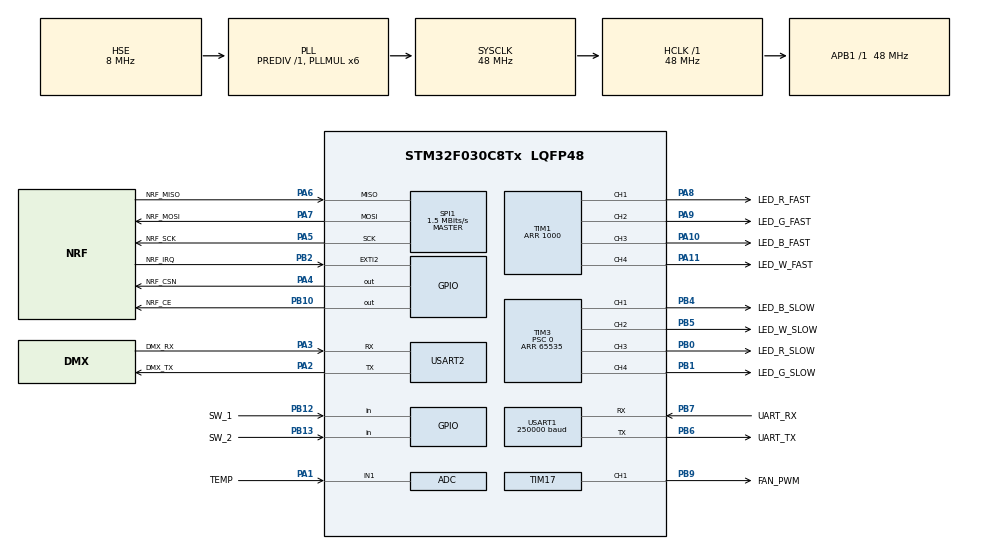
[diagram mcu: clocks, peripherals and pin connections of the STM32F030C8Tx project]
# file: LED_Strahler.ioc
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ADC.ContinuousConvMode=ENABLE
Dma.Request0=USART1_RX
Dma.Request1=USART1_TX
Dma.Request2=SPI1_RX
Dma.Request3=SPI1_TX
Dma.SPI1_RX.2.Direction=DMA_PERIPH_TO_MEMORY
Dma.SPI1_RX.2.Instance=DMA1_Channel2
Dma.SPI1_RX.2.MemDataAlignment=DMA_MDATAALIGN_BYTE
Dma.SPI1_RX.2.MemInc=DMA_MINC_ENABLE
Dma.SPI1_RX.2.Mode=DMA_NORMAL
Dma.SPI1_RX.2.PeriphDataAlignment=DMA_PDATAALIGN_BYTE
Dma.SPI1_RX.2.PeriphInc=DMA_PINC_DISABLE
Dma.SPI1_RX.2.Priority=DMA_PRIORITY_LOW
Dma.SPI1_TX.3.Direction=DMA_MEMORY_TO_PERIPH
Dma.SPI1_TX.3.Instance=DMA1_Channel3
Dma.SPI1_TX.3.MemDataAlignment=DMA_MDATAALIGN_BYTE
Dma.SPI1_TX.3.MemInc=DMA_MINC_ENABLE
Dma.SPI1_TX.3.Mode=DMA_NORMAL
Dma.SPI1_TX.3.PeriphDataAlignment=DMA_PDATAALIGN_BYTE
Dma.SPI1_TX.3.PeriphInc=DMA_PINC_DISABLE
Dma.SPI1_TX.3.Priority=DMA_PRIORITY_LOW
Dma.USART1_RX.0.Direction=DMA_PERIPH_TO_MEMORY
Dma.USART1_RX.0.Instance=DMA1_Channel5
Dma.USART1_RX.0.MemDataAlignment=DMA_MDATAALIGN_BYTE
Dma.USART1_RX.0.MemInc=DMA_MINC_ENABLE
Dma.USART1_RX.0.Mode=DMA_CIRCULAR
Dma.USART1_RX.0.PeriphDataAlignment=DMA_PDATAALIGN_BYTE
Dma.USART1_RX.0.PeriphInc=DMA_PINC_DISABLE
Dma.USART1_RX.0.Priority=DMA_PRIORITY_MEDIUM
Dma.USART1_TX.1.Direction=DMA_MEMORY_TO_PERIPH
Dma.USART1_TX.1.Instance=DMA1_Channel4
Dma.USART1_TX.1.MemDataAlignment=DMA_MDATAALIGN_BYTE
Dma.USART1_TX.1.MemInc=DMA_MINC_ENABLE
Dma.USART1_TX.1.Mode=DMA_CIRCULAR
Dma.USART1_TX.1.PeriphDataAlignment=DMA_PDATAALIGN_BYTE
Dma.USART1_TX.1.PeriphInc=DMA_PINC_DISABLE
Dma.USART1_TX.1.Priority=DMA_PRIORITY_MEDIUM
Mcu.Family=STM32F0
Mcu.Name=STM32F030C8Tx
Mcu.Package=LQFP48
NVIC.DMA1_Channel2_3_IRQn=true\:0\:0\:false\:false\:true\:false\:true
NVIC.DMA1_Channel4_5_IRQn=true\:0\:0\:false\:false\:true\:false\:true
NVIC.EXTI2_3_IRQn=true\:1\:0\:true\:false\:true\:true\:true
PA1.GPIO_Label=TEMP
PA1.Mode=IN1
PA1.Signal=ADC_IN1
PA10.GPIO_Label=LED_B_FAST
PA10.GPIO_ModeDefaultPP=GPIO_MODE_AF_PP
PA10.GPIO_Speed=GPIO_SPEED_FREQ_HIGH
PA10.Signal=S_TIM1_CH3
PA11.GPIO_Label=LED_W_FAST
PA11.GPIO_ModeDefaultPP=GPIO_MODE_AF_PP
PA11.GPIO_Speed=GPIO_SPEED_FREQ_HIGH
PA11.Signal=S_TIM1_CH4
PA13.Mode=Serial_Wire
PA13.Signal=SYS_SWDIO
PA14.Mode=Serial_Wire
PA14.Signal=SYS_SWCLK
PA2.GPIO_Label=DMX_TX
PA2.Mode=Asynchronous
PA2.Signal=USART2_TX
PA3.GPIO_Label=DMX_RX
PA3.GPIO_ModeDefaultPP=GPIO_MODE_AF_OD
PA3.GPIO_PuPd=GPIO_PULLUP
PA3.Mode=Asynchronous
PA3.Signal=USART2_RX
PA4.GPIO_Label=NRF_CSN
PA4.GPIO_Speed=GPIO_SPEED_FREQ_MEDIUM
PA4.PinState=GPIO_PIN_SET
PA4.Signal=GPIO_Output
PA5.GPIO_Label=NRF_SCK
PA5.Mode=Full_Duplex_Master
PA5.Signal=SPI1_SCK
PA6.GPIO_Label=NRF_MISO
PA6.Mode=Full_Duplex_Master
PA6.Signal=SPI1_MISO
PA7.GPIO_Label=NRF_MOSI
PA7.Mode=Full_Duplex_Master
PA7.Signal=SPI1_MOSI
PA8.GPIO_Label=LED_R_FAST
PA8.GPIO_ModeDefaultPP=GPIO_MODE_AF_PP
PA8.GPIO_Speed=GPIO_SPEED_FREQ_HIGH
PA8.Signal=S_TIM1_CH1
PA9.GPIO_Label=LED_G_FAST
PA9.GPIO_ModeDefaultPP=GPIO_MODE_AF_PP
PA9.GPIO_Speed=GPIO_SPEED_FREQ_HIGH
PA9.Signal=S_TIM1_CH2
PB0.GPIO_Label=LED_R_SLOW
PB0.GPIO_ModeDefaultPP=GPIO_MODE_AF_OD
PB0.GPIO_Speed=GPIO_SPEED_FREQ_LOW
PB0.Signal=S_TIM3_CH3
PB1.GPIO_Label=LED_G_SLOW
PB1.GPIO_ModeDefaultPP=GPIO_MODE_AF_OD
PB1.GPIO_Speed=GPIO_SPEED_FREQ_LOW
PB1.Signal=S_TIM3_CH4
PB10.GPIO_Label=NRF_CE
PB10.GPIO_Speed=GPIO_SPEED_FREQ_MEDIUM
PB10.Signal=GPIO_Output
PB12.GPIO_Label=SW_1
PB12.GPIO_PuPd=GPIO_PULLUP
PB12.Signal=GPIO_Input
PB13.GPIO_Label=SW_2
PB13.GPIO_PuPd=GPIO_PULLUP
PB13.Signal=GPIO_Input
PB2.GPIO_Label=NRF_IRQ
PB2.GPIO_ModeDefaultEXTI=GPIO_MODE_IT_FALLING
PB2.GPIO_PuPd=GPIO_PULLUP
PB2.Signal=GPXTI2
PB4.GPIO_Label=LED_B_SLOW
PB4.GPIO_ModeDefaultPP=GPIO_MODE_AF_OD
PB4.Signal=S_TIM3_CH1
PB5.GPIO_Label=LED_W_SLOW
PB5.GPIO_ModeDefaultPP=GPIO_MODE_AF_OD
PB5.Signal=S_TIM3_CH2
PB6.GPIO_Label=UART_TX
PB6.Mode=Asynchronous
PB6.Signal=USART1_TX
PB7.GPIO_Label=UART_RX
PB7.GPIO_ModeDefaultPP=GPIO_MODE_AF_OD
PB7.GPIO_PuPd=GPIO_PULLUP
PB7.Mode=Asynchronous
PB7.Signal=USART1_RX
PB9.GPIO_Label=FAN_PWM
PB9.GPIO_PuPd=GPIO_PULLUP
PB9.GPIO_Speed=GPIO_SPEED_FREQ_MEDIUM
PB9.Signal=S_TIM17_CH1
PF0-OSC_IN.GPIO_Label=OSC_IN
PF0-OSC_IN.Mode=HSE-External-Oscillator
PF0-OSC_IN.Signal=RCC_OSC_IN
PF1-OSC_OUT.GPIO_Label=OSC_OUT
PF1-OSC_OUT.Mode=HSE-External-Oscillator
PF1-OSC_OUT.Signal=RCC_OSC_OUT
ProjectManager.HeapSize=0x200
ProjectManager.StackSize=0x400
ProjectManager.TargetToolchain=STM32CubeIDE
RCC.AHBFreq_Value=48000000
RCC.APB1Freq_Value=48000000
RCC.APB1TimFreq_Value=48000000
RCC.HCLKFreq_Value=48000000
RCC.PLLMUL=RCC_PLL_MUL6
RCC.PLLSourceVirtual=RCC_PLLSOURCE_HSE
RCC.SYSCLKFreq_VALUE=48000000
RCC.SYSCLKSource=RCC_SYSCLKSOURCE_PLLCLK
RCC.TimSys_Div=SYSTICK_CLKSOURCE_HCLK_DIV8
SH.S_TIM17_CH1.0=TIM17_CH1,PWM Generation1 CH1
SH.S_TIM1_CH1.0=TIM1_CH1,PWM Generation1 CH1
SH.S_TIM1_CH2.0=TIM1_CH2,PWM Generation2 CH2
SH.S_TIM1_CH3.0=TIM1_CH3,PWM Generation3 CH3
SH.S_TIM1_CH4.0=TIM1_CH4,PWM Generation4 CH4
SH.S_TIM3_CH1.0=TIM3_CH1,PWM Generation1 CH1
SH.S_TIM3_CH2.0=TIM3_CH2,PWM Generation2 CH2
SH.S_TIM3_CH3.0=TIM3_CH3,PWM Generation3 CH3
SH.S_TIM3_CH4.0=TIM3_CH4,PWM Generation4 CH4
SPI1.BaudRatePrescaler=SPI_BAUDRATEPRESCALER_32
SPI1.CalculateBaudRate=1.5 MBits/s
SPI1.DataSize=SPI_DATASIZE_8BIT
SPI1.Direction=SPI_DIRECTION_2LINES
SPI1.Mode=SPI_MODE_MASTER
SPI1.NSSPMode=SPI_NSS_PULSE_DISABLE
SPI1.VirtualType=VM_MASTER
TIM1.AutoReloadPreload=TIM_AUTORELOAD_PRELOAD_ENABLE
TIM1.Channel-PWM\ Generation1\ CH1=TIM_CHANNEL_1
TIM1.Channel-PWM\ Generation2\ CH2=TIM_CHANNEL_2
TIM1.Channel-PWM\ Generation3\ CH3=TIM_CHANNEL_3
TIM1.Channel-PWM\ Generation4\ CH4=TIM_CHANNEL_4
TIM1.Period=1000
TIM17.AutoReloadPreload=TIM_AUTORELOAD_PRELOAD_ENABLE
TIM17.Channel=TIM_CHANNEL_1
TIM17.OCFastMode_PWM=TIM_OCFAST_ENABLE
TIM17.Period=1920
TIM3.AutoReloadPreload=TIM_AUTORELOAD_PRELOAD_ENABLE
TIM3.Channel-PWM\ Generation1\ CH1=TIM_CHANNEL_1
TIM3.Channel-PWM\ Generation2\ CH2=TIM_CHANNEL_2
TIM3.Channel-PWM\ Generation3\ CH3=TIM_CHANNEL_3
TIM3.Channel-PWM\ Generation4\ CH4=TIM_CHANNEL_4
TIM3.OCPolarity_1=TIM_OCPOLARITY_HIGH
TIM3.OCPolarity_2=TIM_OCPOLARITY_HIGH
TIM3.OCPolarity_3=TIM_OCPOLARITY_HIGH
TIM3.OCPolarity_4=TIM_OCPOLARITY_HIGH
TIM3.Period=65535
TIM3.Prescaler=0
USART1.BaudRate=250000
USART1.VirtualMode-Asynchronous=VM_ASYNC
USART2.VirtualMode-Asynchronous=VM_ASYNC
VP_TIM17_VS_ClockSourceINT.Mode=Enable_Timer
VP_TIM1_VS_ClockSourceINT.Mode=Internal
VP_TIM3_VS_ClockSourceINT.Mode=Internal
board=custom

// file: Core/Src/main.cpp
/* USER CODE BEGIN Header */
/**
  ******************************************************************************
  * @file           : main.c
  * @brief          : Main program body
  ******************************************************************************
  * @attention
  *
  * <h2><center>&copy; Copyright (c) 2019 STMicroelectronics.
  * All rights reserved.</center></h2>
  *
  * This software component is licensed by ST under BSD 3-Clause license,
  * the "License"; You may not use this file except in compliance with the
  * License. You may obtain a copy of the License at:
  *                        opensource.org/licenses/BSD-3-Clause
  *
  ******************************************************************************
  */
/* USER CODE END Header */

#include "main.h"

/* USER CODE BEGIN Includes */
#include "LED_StateMachine.h"
#include "LED_Thermomodel.h"
/* USER CODE END Includes */

ADC_HandleTypeDef hadc;

SPI_HandleTypeDef hspi1;
DMA_HandleTypeDef hdma_spi1_rx;
DMA_HandleTypeDef hdma_spi1_tx;

TIM_HandleTypeDef htim1;
TIM_HandleTypeDef htim3;
TIM_HandleTypeDef htim17;

UART_HandleTypeDef huart1;
UART_HandleTypeDef huart2;
DMA_HandleTypeDef hdma_usart1_rx;
DMA_HandleTypeDef hdma_usart1_tx;

void SystemClock_Config(void);
static void MX_GPIO_Init(void);
static void MX_DMA_Init(void);
static void MX_ADC_Init(void);
static void MX_SPI1_Init(void);
static void MX_TIM1_Init(void);
static void MX_TIM3_Init(void);
static void MX_USART1_UART_Init(void);
static void MX_TIM17_Init(void);
static void MX_USART2_UART_Init(void);

int main(void)
{

  /* MCU Configuration--------------------------------------------------------*/

  /* Reset of all peripherals, Initializes the Flash interface and the Systick. */
  HAL_Init();

  /* Configure the system clock */
  SystemClock_Config();

  /* Initialize all configured peripherals */
  MX_GPIO_Init();
  MX_DMA_Init();
  MX_ADC_Init();
  MX_SPI1_Init();
  MX_TIM1_Init();
  MX_TIM3_Init();
  MX_USART1_UART_Init();
  MX_TIM17_Init();
  MX_USART2_UART_Init();
  /* USER CODE BEGIN 2 */

  LED_Thermomodel_Init();
  LED_StateMachine_Init();

  /* USER CODE END 2 */

  /* Infinite loop */
  /* USER CODE BEGIN WHILE */
	while (1)
	{
		LED_StateMachine_Handle();
		LED_Thermomodel_Handle();
    /* USER CODE END WHILE */

	}
}

void SystemClock_Config(void)
{
  RCC_OscInitTypeDef RCC_OscInitStruct = {0};
  RCC_ClkInitTypeDef RCC_ClkInitStruct = {0};
  RCC_PeriphCLKInitTypeDef PeriphClkInit = {0};

  /** Initializes the CPU, AHB and APB busses clocks
  */
  RCC_OscInitStruct.OscillatorType = RCC_OSCILLATORTYPE_HSI14|RCC_OSCILLATORTYPE_HSE;
  RCC_OscInitStruct.HSEState = RCC_HSE_ON;
  RCC_OscInitStruct.HSI14State = RCC_HSI14_ON;
  RCC_OscInitStruct.HSI14CalibrationValue = 16;
  RCC_OscInitStruct.PLL.PLLState = RCC_PLL_ON;
  RCC_OscInitStruct.PLL.PLLSource = RCC_PLLSOURCE_HSE;
  RCC_OscInitStruct.PLL.PLLMUL = RCC_PLL_MUL6;
  RCC_OscInitStruct.PLL.PREDIV = RCC_PREDIV_DIV1;
  if (HAL_RCC_OscConfig(&RCC_OscInitStruct) != HAL_OK)
  {
    Error_Handler();
  }
  /** Initializes the CPU, AHB and APB busses clocks
  */
  RCC_ClkInitStruct.ClockType = RCC_CLOCKTYPE_HCLK|RCC_CLOCKTYPE_SYSCLK
                              |RCC_CLOCKTYPE_PCLK1;
  RCC_ClkInitStruct.SYSCLKSource = RCC_SYSCLKSOURCE_PLLCLK;
  RCC_ClkInitStruct.AHBCLKDivider = RCC_SYSCLK_DIV1;
  RCC_ClkInitStruct.APB1CLKDivider = RCC_HCLK_DIV1;

  if (HAL_RCC_ClockConfig(&RCC_ClkInitStruct, FLASH_LATENCY_1) != HAL_OK)
  {
    Error_Handler();
  }
  PeriphClkInit.PeriphClockSelection = RCC_PERIPHCLK_USART1;
  PeriphClkInit.Usart1ClockSelection = RCC_USART1CLKSOURCE_PCLK1;
  if (HAL_RCCEx_PeriphCLKConfig(&PeriphClkInit) != HAL_OK)
  {
    Error_Handler();
  }
}

static void MX_ADC_Init(void)
{

  ADC_ChannelConfTypeDef sConfig = {0};

  /** Configure the global features of the ADC (Clock, Resolution, Data Alignment and number of conversion)
  */
  hadc.Instance = ADC1;
  hadc.Init.ClockPrescaler = ADC_CLOCK_ASYNC_DIV1;
  hadc.Init.Resolution = ADC_RESOLUTION_12B;
  hadc.Init.DataAlign = ADC_DATAALIGN_RIGHT;
  hadc.Init.ScanConvMode = ADC_SCAN_DIRECTION_FORWARD;
  hadc.Init.EOCSelection = ADC_EOC_SINGLE_CONV;
  hadc.Init.LowPowerAutoWait = DISABLE;
  hadc.Init.LowPowerAutoPowerOff = DISABLE;
  hadc.Init.ContinuousConvMode = ENABLE;
  hadc.Init.DiscontinuousConvMode = DISABLE;
  hadc.Init.ExternalTrigConv = ADC_SOFTWARE_START;
  hadc.Init.ExternalTrigConvEdge = ADC_EXTERNALTRIGCONVEDGE_NONE;
  hadc.Init.DMAContinuousRequests = DISABLE;
  hadc.Init.Overrun = ADC_OVR_DATA_PRESERVED;
  if (HAL_ADC_Init(&hadc) != HAL_OK)
  {
    Error_Handler();
  }
  /** Configure for the selected ADC regular channel to be converted.
  */
  sConfig.Channel = ADC_CHANNEL_1;
  sConfig.Rank = ADC_RANK_CHANNEL_NUMBER;
  sConfig.SamplingTime = ADC_SAMPLETIME_1CYCLE_5;
  if (HAL_ADC_ConfigChannel(&hadc, &sConfig) != HAL_OK)
  {
    Error_Handler();
  }

}

static void MX_SPI1_Init(void)
{

  /* SPI1 parameter configuration*/
  hspi1.Instance = SPI1;
  hspi1.Init.Mode = SPI_MODE_MASTER;
  hspi1.Init.Direction = SPI_DIRECTION_2LINES;
  hspi1.Init.DataSize = SPI_DATASIZE_8BIT;
  hspi1.Init.CLKPolarity = SPI_POLARITY_LOW;
  hspi1.Init.CLKPhase = SPI_PHASE_1EDGE;
  hspi1.Init.NSS = SPI_NSS_SOFT;
  hspi1.Init.BaudRatePrescaler = SPI_BAUDRATEPRESCALER_32;
  hspi1.Init.FirstBit = SPI_FIRSTBIT_MSB;
  hspi1.Init.TIMode = SPI_TIMODE_DISABLE;
  hspi1.Init.CRCCalculation = SPI_CRCCALCULATION_DISABLE;
  hspi1.Init.CRCPolynomial = 7;
  hspi1.Init.CRCLength = SPI_CRC_LENGTH_DATASIZE;
  hspi1.Init.NSSPMode = SPI_NSS_PULSE_DISABLE;
  if (HAL_SPI_Init(&hspi1) != HAL_OK)
  {
    Error_Handler();
  }
  /* USER CODE BEGIN SPI1_Init 2 */
  /* full duplex master, 8 bit transfer, default phase and polarity */
  hspi1.Instance->CR1 |= SPI_CR1_MSTR | SPI_CR1_SPE | SPI_CR1_SSM | SPI_CR1_SSI;
  /* Disable receive FIFO, it'd complicate things when there is an odd number of bytes to transfer */
  hspi1.Instance->CR2 |= SPI_CR2_FRXTH;
  /* USER CODE END SPI1_Init 2 */

}

static void MX_TIM1_Init(void)
{

  TIM_ClockConfigTypeDef sClockSourceConfig = {0};
  TIM_MasterConfigTypeDef sMasterConfig = {0};
  TIM_OC_InitTypeDef sConfigOC = {0};
  TIM_BreakDeadTimeConfigTypeDef sBreakDeadTimeConfig = {0};

  htim1.Instance = TIM1;
  htim1.Init.Prescaler = 0;
  htim1.Init.CounterMode = TIM_COUNTERMODE_UP;
  htim1.Init.Period = 1000;
  htim1.Init.ClockDivision = TIM_CLOCKDIVISION_DIV1;
  htim1.Init.RepetitionCounter = 0;
  htim1.Init.AutoReloadPreload = TIM_AUTORELOAD_PRELOAD_ENABLE;
  if (HAL_TIM_Base_Init(&htim1) != HAL_OK)
  {
    Error_Handler();
  }
  sClockSourceConfig.ClockSource = TIM_CLOCKSOURCE_INTERNAL;
  if (HAL_TIM_ConfigClockSource(&htim1, &sClockSourceConfig) != HAL_OK)
  {
    Error_Handler();
  }
  if (HAL_TIM_PWM_Init(&htim1) != HAL_OK)
  {
    Error_Handler();
  }
  sMasterConfig.MasterOutputTrigger = TIM_TRGO_RESET;
  sMasterConfig.MasterSlaveMode = TIM_MASTERSLAVEMODE_DISABLE;
  if (HAL_TIMEx_MasterConfigSynchronization(&htim1, &sMasterConfig) != HAL_OK)
  {
    Error_Handler();
  }
  sConfigOC.OCMode = TIM_OCMODE_PWM1;
  sConfigOC.Pulse = 0;
  sConfigOC.OCPolarity = TIM_OCPOLARITY_HIGH;
  sConfigOC.OCNPolarity = TIM_OCNPOLARITY_HIGH;
  sConfigOC.OCFastMode = TIM_OCFAST_DISABLE;
  sConfigOC.OCIdleState = TIM_OCIDLESTATE_RESET;
  sConfigOC.OCNIdleState = TIM_OCNIDLESTATE_RESET;
  if (HAL_TIM_PWM_ConfigChannel(&htim1, &sConfigOC, TIM_CHANNEL_1) != HAL_OK)
  {
    Error_Handler();
  }
  if (HAL_TIM_PWM_ConfigChannel(&htim1, &sConfigOC, TIM_CHANNEL_2) != HAL_OK)
  {
    Error_Handler();
  }
  if (HAL_TIM_PWM_ConfigChannel(&htim1, &sConfigOC, TIM_CHANNEL_3) != HAL_OK)
  {
    Error_Handler();
  }
  if (HAL_TIM_PWM_ConfigChannel(&htim1, &sConfigOC, TIM_CHANNEL_4) != HAL_OK)
  {
    Error_Handler();
  }
  sBreakDeadTimeConfig.OffStateRunMode = TIM_OSSR_DISABLE;
  sBreakDeadTimeConfig.OffStateIDLEMode = TIM_OSSI_DISABLE;
  sBreakDeadTimeConfig.LockLevel = TIM_LOCKLEVEL_OFF;
  sBreakDeadTimeConfig.DeadTime = 0;
  sBreakDeadTimeConfig.BreakState = TIM_BREAK_DISABLE;
  sBreakDeadTimeConfig.BreakPolarity = TIM_BREAKPOLARITY_HIGH;
  sBreakDeadTimeConfig.AutomaticOutput = TIM_AUTOMATICOUTPUT_DISABLE;
  if (HAL_TIMEx_ConfigBreakDeadTime(&htim1, &sBreakDeadTimeConfig) != HAL_OK)
  {
    Error_Handler();
  }
  HAL_TIM_MspPostInit(&htim1);

}

static void MX_TIM3_Init(void)
{

  TIM_ClockConfigTypeDef sClockSourceConfig = {0};
  TIM_MasterConfigTypeDef sMasterConfig = {0};
  TIM_OC_InitTypeDef sConfigOC = {0};

  htim3.Instance = TIM3;
  htim3.Init.Prescaler = 0;
  htim3.Init.CounterMode = TIM_COUNTERMODE_UP;
  htim3.Init.Period = 65535;
  htim3.Init.ClockDivision = TIM_CLOCKDIVISION_DIV1;
  htim3.Init.AutoReloadPreload = TIM_AUTORELOAD_PRELOAD_ENABLE;
  if (HAL_TIM_Base_Init(&htim3) != HAL_OK)
  {
    Error_Handler();
  }
  sClockSourceConfig.ClockSource = TIM_CLOCKSOURCE_INTERNAL;
  if (HAL_TIM_ConfigClockSource(&htim3, &sClockSourceConfig) != HAL_OK)
  {
    Error_Handler();
  }
  if (HAL_TIM_PWM_Init(&htim3) != HAL_OK)
  {
    Error_Handler();
  }
  sMasterConfig.MasterOutputTrigger = TIM_TRGO_RESET;
  sMasterConfig.MasterSlaveMode = TIM_MASTERSLAVEMODE_DISABLE;
  if (HAL_TIMEx_MasterConfigSynchronization(&htim3, &sMasterConfig) != HAL_OK)
  {
    Error_Handler();
  }
  sConfigOC.OCMode = TIM_OCMODE_PWM1;
  sConfigOC.Pulse = 0;
  sConfigOC.OCPolarity = TIM_OCPOLARITY_HIGH;
  sConfigOC.OCFastMode = TIM_OCFAST_DISABLE;
  if (HAL_TIM_PWM_ConfigChannel(&htim3, &sConfigOC, TIM_CHANNEL_1) != HAL_OK)
  {
    Error_Handler();
  }
  if (HAL_TIM_PWM_ConfigChannel(&htim3, &sConfigOC, TIM_CHANNEL_2) != HAL_OK)
  {
    Error_Handler();
  }
  if (HAL_TIM_PWM_ConfigChannel(&htim3, &sConfigOC, TIM_CHANNEL_3) != HAL_OK)
  {
    Error_Handler();
  }
  if (HAL_TIM_PWM_ConfigChannel(&htim3, &sConfigOC, TIM_CHANNEL_4) != HAL_OK)
  {
    Error_Handler();
  }
  HAL_TIM_MspPostInit(&htim3);

}

static void MX_TIM17_Init(void)
{

  TIM_OC_InitTypeDef sConfigOC = {0};
  TIM_BreakDeadTimeConfigTypeDef sBreakDeadTimeConfig = {0};

  htim17.Instance = TIM17;
  htim17.Init.Prescaler = 0;
  htim17.Init.CounterMode = TIM_COUNTERMODE_UP;
  htim17.Init.Period = 1920;
  htim17.Init.ClockDivision = TIM_CLOCKDIVISION_DIV1;
  htim17.Init.RepetitionCounter = 0;
  htim17.Init.AutoReloadPreload = TIM_AUTORELOAD_PRELOAD_ENABLE;
  if (HAL_TIM_Base_Init(&htim17) != HAL_OK)
  {
    Error_Handler();
  }
  if (HAL_TIM_PWM_Init(&htim17) != HAL_OK)
  {
    Error_Handler();
  }
  sConfigOC.OCMode = TIM_OCMODE_PWM1;
  sConfigOC.Pulse = 0;
  sConfigOC.OCPolarity = TIM_OCPOLARITY_HIGH;
  sConfigOC.OCNPolarity = TIM_OCNPOLARITY_HIGH;
  sConfigOC.OCFastMode = TIM_OCFAST_ENABLE;
  sConfigOC.OCIdleState = TIM_OCIDLESTATE_RESET;
  sConfigOC.OCNIdleState = TIM_OCNIDLESTATE_RESET;
  if (HAL_TIM_PWM_ConfigChannel(&htim17, &sConfigOC, TIM_CHANNEL_1) != HAL_OK)
  {
    Error_Handler();
  }
  sBreakDeadTimeConfig.OffStateRunMode = TIM_OSSR_DISABLE;
  sBreakDeadTimeConfig.OffStateIDLEMode = TIM_OSSI_DISABLE;
  sBreakDeadTimeConfig.LockLevel = TIM_LOCKLEVEL_OFF;
  sBreakDeadTimeConfig.DeadTime = 0;
  sBreakDeadTimeConfig.BreakState = TIM_BREAK_DISABLE;
  sBreakDeadTimeConfig.BreakPolarity = TIM_BREAKPOLARITY_HIGH;
  sBreakDeadTimeConfig.AutomaticOutput = TIM_AUTOMATICOUTPUT_DISABLE;
  if (HAL_TIMEx_ConfigBreakDeadTime(&htim17, &sBreakDeadTimeConfig) != HAL_OK)
  {
    Error_Handler();
  }
  HAL_TIM_MspPostInit(&htim17);

}

static void MX_USART1_UART_Init(void)
{

  huart1.Instance = USART1;
  huart1.Init.BaudRate = 250000;
  huart1.Init.WordLength = UART_WORDLENGTH_8B;
  huart1.Init.StopBits = UART_STOPBITS_1;
  huart1.Init.Parity = UART_PARITY_NONE;
  huart1.Init.Mode = UART_MODE_TX_RX;
  huart1.Init.HwFlowCtl = UART_HWCONTROL_NONE;
  huart1.Init.OverSampling = UART_OVERSAMPLING_16;
  huart1.Init.OneBitSampling = UART_ONE_BIT_SAMPLE_DISABLE;
  huart1.AdvancedInit.AdvFeatureInit = UART_ADVFEATURE_NO_INIT;
  if (HAL_UART_Init(&huart1) != HAL_OK)
  {
    Error_Handler();
  }

}

static void MX_USART2_UART_Init(void)
{

  huart2.Instance = USART2;
  huart2.Init.BaudRate = 38400;
  huart2.Init.WordLength = UART_WORDLENGTH_8B;
  huart2.Init.StopBits = UART_STOPBITS_1;
  huart2.Init.Parity = UART_PARITY_NONE;
  huart2.Init.Mode = UART_MODE_TX_RX;
  huart2.Init.HwFlowCtl = UART_HWCONTROL_NONE;
  huart2.Init.OverSampling = UART_OVERSAMPLING_16;
  huart2.Init.OneBitSampling = UART_ONE_BIT_SAMPLE_DISABLE;
  huart2.AdvancedInit.AdvFeatureInit = UART_ADVFEATURE_NO_INIT;
  if (HAL_UART_Init(&huart2) != HAL_OK)
  {
    Error_Handler();
  }

}

static void MX_DMA_Init(void)
{

  /* DMA controller clock enable */
  __HAL_RCC_DMA1_CLK_ENABLE();

  /* DMA interrupt init */
  /* DMA1_Channel2_3_IRQn interrupt configuration */
  HAL_NVIC_SetPriority(DMA1_Channel2_3_IRQn, 0, 0);
  HAL_NVIC_EnableIRQ(DMA1_Channel2_3_IRQn);
  /* DMA1_Channel4_5_IRQn interrupt configuration */
  HAL_NVIC_SetPriority(DMA1_Channel4_5_IRQn, 0, 0);
  HAL_NVIC_EnableIRQ(DMA1_Channel4_5_IRQn);

}

static void MX_GPIO_Init(void)
{
  GPIO_InitTypeDef GPIO_InitStruct = {0};

  /* GPIO Ports Clock Enable */
  __HAL_RCC_GPIOF_CLK_ENABLE();
  __HAL_RCC_GPIOA_CLK_ENABLE();
  __HAL_RCC_GPIOB_CLK_ENABLE();

  /*Configure GPIO pin Output Level */
  HAL_GPIO_WritePin(NRF_CSN_GPIO_Port, NRF_CSN_Pin, GPIO_PIN_SET);

  /*Configure GPIO pin Output Level */
  HAL_GPIO_WritePin(NRF_CE_GPIO_Port, NRF_CE_Pin, GPIO_PIN_RESET);

  /*Configure GPIO pin : NRF_CSN_Pin */
  GPIO_InitStruct.Pin = NRF_CSN_Pin;
  GPIO_InitStruct.Mode = GPIO_MODE_OUTPUT_PP;
  GPIO_InitStruct.Pull = GPIO_NOPULL;
  GPIO_InitStruct.Speed = GPIO_SPEED_FREQ_MEDIUM;
  HAL_GPIO_Init(NRF_CSN_GPIO_Port, &GPIO_InitStruct);

  /*Configure GPIO pin : NRF_IRQ_Pin */
  GPIO_InitStruct.Pin = NRF_IRQ_Pin;
  GPIO_InitStruct.Mode = GPIO_MODE_IT_FALLING;
  GPIO_InitStruct.Pull = GPIO_PULLUP;
  HAL_GPIO_Init(NRF_IRQ_GPIO_Port, &GPIO_InitStruct);

  /*Configure GPIO pin : NRF_CE_Pin */
  GPIO_InitStruct.Pin = NRF_CE_Pin;
  GPIO_InitStruct.Mode = GPIO_MODE_OUTPUT_PP;
  GPIO_InitStruct.Pull = GPIO_NOPULL;
  GPIO_InitStruct.Speed = GPIO_SPEED_FREQ_MEDIUM;
  HAL_GPIO_Init(NRF_CE_GPIO_Port, &GPIO_InitStruct);

  /*Configure GPIO pins : SW_1_Pin SW_2_Pin */
  GPIO_InitStruct.Pin = SW_1_Pin|SW_2_Pin;
  GPIO_InitStruct.Mode = GPIO_MODE_INPUT;
  GPIO_InitStruct.Pull = GPIO_PULLUP;
  HAL_GPIO_Init(GPIOB, &GPIO_InitStruct);

  /* EXTI interrupt init*/
  HAL_NVIC_SetPriority(EXTI2_3_IRQn, 1, 0);
  HAL_NVIC_EnableIRQ(EXTI2_3_IRQn);

}

void Error_Handler(void)
{
}

/************************ (C) COPYRIGHT STMicroelectronics *****END OF FILE****/
